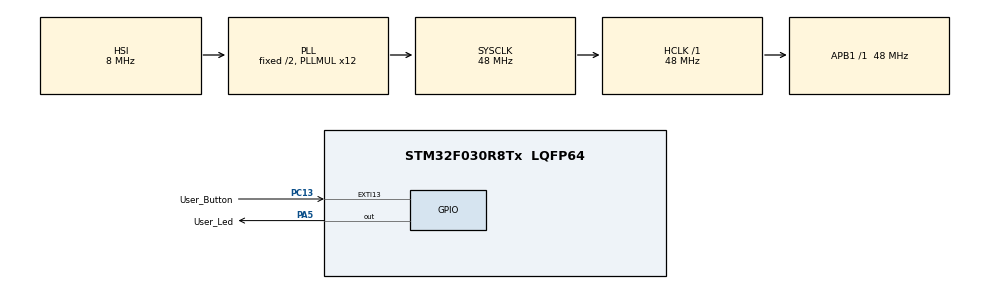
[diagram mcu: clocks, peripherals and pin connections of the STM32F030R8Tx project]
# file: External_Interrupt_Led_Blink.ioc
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Mcu.Family=STM32F0
Mcu.Name=STM32F030R8Tx
Mcu.Package=LQFP64
NVIC.EXTI4_15_IRQn=true\:0\:0\:false\:false\:true\:true\:true\:true
PA13.Mode=Serial_Wire
PA13.Signal=SYS_SWDIO
PA14.Mode=Serial_Wire
PA14.Signal=SYS_SWCLK
PA5.GPIO_Label=User_Led
PA5.GPIO_Speed=GPIO_SPEED_FREQ_MEDIUM
PA5.Signal=GPIO_Output
PC13.GPIO_Label=User_Button
PC13.GPIO_ModeDefaultEXTI=GPIO_MODE_IT_RISING
PC13.GPIO_PuPd=GPIO_PULLDOWN
PC13.Signal=GPXTI13
ProjectManager.HeapSize=0x200
ProjectManager.StackSize=0x400
ProjectManager.TargetToolchain=STM32CubeIDE
RCC.AHBFreq_Value=48000000
RCC.APB1Freq_Value=48000000
RCC.APB1TimFreq_Value=48000000
RCC.HCLKFreq_Value=48000000
RCC.PLLMUL=RCC_PLL_MUL12
RCC.SYSCLKFreq_VALUE=48000000
RCC.SYSCLKSource=RCC_SYSCLKSOURCE_PLLCLK
board=NUCLEO-F030R8

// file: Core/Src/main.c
/* USER CODE BEGIN Header */
/**
 ******************************************************************************
 * @file           : main.c
 * @brief          : Main program body
 ******************************************************************************
 * @attention
 *
 * Copyright (c) 2025 STMicroelectronics.
 * All rights reserved.
 *
 * This software is licensed under terms that can be found in the LICENSE file
 * in the root directory of this software component.
 * If no LICENSE file comes with this software, it is provided AS-IS.
 *
 ******************************************************************************
 */
/* USER CODE END Header */
#include "main.h"

/* USER CODE BEGIN Includes */
//trying
/* USER CODE END Includes */

/* USER CODE BEGIN PV */
uint8_t interrupt_flag = 0;
/* USER CODE END PV */

void SystemClock_Config(void);
static void MX_GPIO_Init(void);

int main(void) {

	/* MCU Configuration--------------------------------------------------------*/

	/* Reset of all peripherals, Initializes the Flash interface and the Systick. */
	HAL_Init();

	/* Configure the system clock */
	SystemClock_Config();

	/* Initialize all configured peripherals */
	MX_GPIO_Init();

	/* Infinite loop */
	while (1) {

		/* USER CODE BEGIN 3 */
		HAL_GPIO_TogglePin(User_Led_GPIO_Port, User_Led_Pin);
		HAL_Delay(500);

		if (interrupt_flag) {
			interrupt_flag = 0;
			HAL_GPIO_TogglePin(User_Led_GPIO_Port, User_Led_Pin);
			HAL_Delay(100);
			HAL_GPIO_TogglePin(User_Led_GPIO_Port, User_Led_Pin);
			HAL_Delay(100);
			HAL_GPIO_TogglePin(User_Led_GPIO_Port, User_Led_Pin);
			HAL_Delay(100);
			HAL_GPIO_TogglePin(User_Led_GPIO_Port, User_Led_Pin);
			HAL_Delay(100);
			HAL_GPIO_TogglePin(User_Led_GPIO_Port, User_Led_Pin);
			HAL_Delay(100);
		}
	}
	/* USER CODE END 3 */
}

void SystemClock_Config(void) {
	RCC_OscInitTypeDef RCC_OscInitStruct = { 0 };
	RCC_ClkInitTypeDef RCC_ClkInitStruct = { 0 };

	/** Initializes the RCC Oscillators according to the specified parameters
	 * in the RCC_OscInitTypeDef structure.
	 */
	RCC_OscInitStruct.OscillatorType = RCC_OSCILLATORTYPE_HSI;
	RCC_OscInitStruct.HSIState = RCC_HSI_ON;
	RCC_OscInitStruct.HSICalibrationValue = RCC_HSICALIBRATION_DEFAULT;
	RCC_OscInitStruct.PLL.PLLState = RCC_PLL_ON;
	RCC_OscInitStruct.PLL.PLLSource = RCC_PLLSOURCE_HSI;
	RCC_OscInitStruct.PLL.PLLMUL = RCC_PLL_MUL12;
	RCC_OscInitStruct.PLL.PREDIV = RCC_PREDIV_DIV1;
	if (HAL_RCC_OscConfig(&RCC_OscInitStruct) != HAL_OK) {
		Error_Handler();
	}

	/** Initializes the CPU, AHB and APB buses clocks
	 */
	RCC_ClkInitStruct.ClockType = RCC_CLOCKTYPE_HCLK | RCC_CLOCKTYPE_SYSCLK
			| RCC_CLOCKTYPE_PCLK1;
	RCC_ClkInitStruct.SYSCLKSource = RCC_SYSCLKSOURCE_PLLCLK;
	RCC_ClkInitStruct.AHBCLKDivider = RCC_SYSCLK_DIV1;
	RCC_ClkInitStruct.APB1CLKDivider = RCC_HCLK_DIV1;

	if (HAL_RCC_ClockConfig(&RCC_ClkInitStruct, FLASH_LATENCY_1) != HAL_OK) {
		Error_Handler();
	}
}

static void MX_GPIO_Init(void) {
	GPIO_InitTypeDef GPIO_InitStruct = { 0 };

	/* GPIO Ports Clock Enable */
	__HAL_RCC_GPIOC_CLK_ENABLE();
	__HAL_RCC_GPIOA_CLK_ENABLE();

	/*Configure GPIO pin Output Level */
	HAL_GPIO_WritePin(User_Led_GPIO_Port, User_Led_Pin, GPIO_PIN_RESET);

	/*Configure GPIO pin : User_Button_Pin */
	GPIO_InitStruct.Pin = User_Button_Pin;
	GPIO_InitStruct.Mode = GPIO_MODE_IT_RISING;
	GPIO_InitStruct.Pull = GPIO_PULLDOWN;
	HAL_GPIO_Init(User_Button_GPIO_Port, &GPIO_InitStruct);

	/*Configure GPIO pin : User_Led_Pin */
	GPIO_InitStruct.Pin = User_Led_Pin;
	GPIO_InitStruct.Mode = GPIO_MODE_OUTPUT_PP;
	GPIO_InitStruct.Pull = GPIO_NOPULL;
	GPIO_InitStruct.Speed = GPIO_SPEED_FREQ_MEDIUM;
	HAL_GPIO_Init(User_Led_GPIO_Port, &GPIO_InitStruct);

	/* EXTI interrupt init*/
	HAL_NVIC_SetPriority(EXTI4_15_IRQn, 0, 0);
	HAL_NVIC_EnableIRQ(EXTI4_15_IRQn);

}

/* USER CODE BEGIN 4 */
// 13ncu pine (PC13) bagli olan butona basildiginda led yanacak. Interrupt fonksiyonlari USER CODE BEGIN 4 kismina Callback fonksiyonu ile yazilir.
void HAL_GPIO_EXTI_Callback(uint16_t GPIO_Pin) {
	if (GPIO_Pin == GPIO_PIN_13) {
		//HAL_GPIO_WritePin(User_Led_GPIO_Port, User_Led_Pin, 1);
		interrupt_flag = 1;
	}

	/* Prevent unused argument(s) compilation warning */
	//UNUSED(GPIO_Pin);
	/* NOTE: This function should not be modified, when the callback is needed,
	 the HAL_GPIO_EXTI_Callback could be implemented in the user file
	 */
}

/* USER CODE END 4 */

void Error_Handler(void) {
	__disable_irq();
	while (1) {
	}
}
